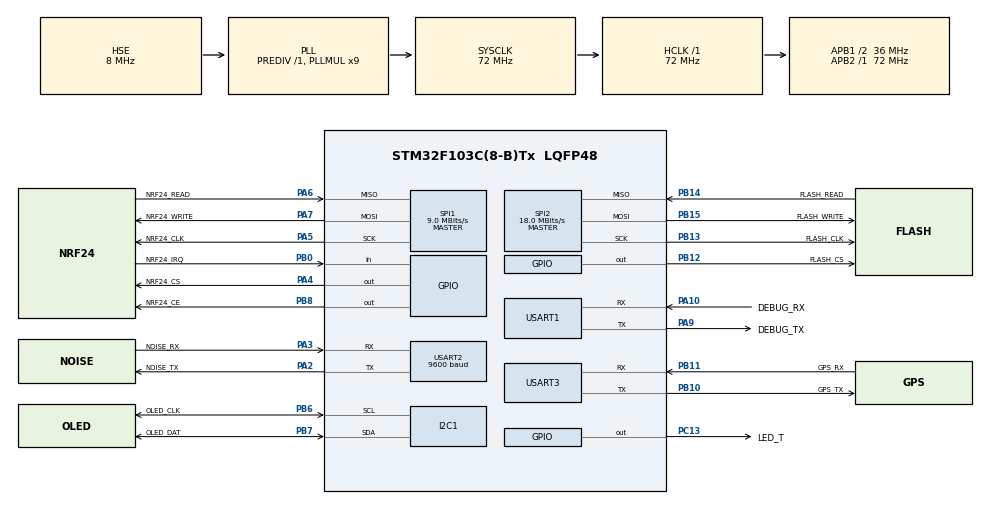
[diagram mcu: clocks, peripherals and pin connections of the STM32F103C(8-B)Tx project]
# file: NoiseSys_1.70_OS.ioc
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Dma.Request0=USART3_RX
Dma.USART3_RX.0.Direction=DMA_PERIPH_TO_MEMORY
Dma.USART3_RX.0.Instance=DMA1_Channel3
Dma.USART3_RX.0.MemDataAlignment=DMA_MDATAALIGN_BYTE
Dma.USART3_RX.0.MemInc=DMA_MINC_ENABLE
Dma.USART3_RX.0.Mode=DMA_NORMAL
Dma.USART3_RX.0.PeriphDataAlignment=DMA_PDATAALIGN_BYTE
Dma.USART3_RX.0.PeriphInc=DMA_PINC_DISABLE
Dma.USART3_RX.0.Priority=DMA_PRIORITY_LOW
FREERTOS.Tasks01=defaultTask,24,128,StartDefaultTask,Default,NULL,Static,defaultTaskBuffer,defaultTaskControlBlock
FREERTOS.configTOTAL_HEAP_SIZE=10240
I2C1.I2C_Mode=I2C_Standard
Mcu.Family=STM32F1
Mcu.Name=STM32F103C(8-B)Tx
Mcu.Package=LQFP48
NVIC.DMA1_Channel3_IRQn=true\:5\:0\:false\:false\:true\:true\:false\:true\:true
NVIC.PriorityGroup=NVIC_PRIORITYGROUP_4
NVIC.TIM4_IRQn=true\:15\:0\:false\:false\:true\:false\:false\:true\:true
NVIC.TimeBase=TIM4_IRQn
NVIC.TimeBaseIP=TIM4
NVIC.USART3_IRQn=true\:5\:0\:false\:false\:true\:true\:true\:true\:true
PA10.GPIO_Label=DEBUG_RX
PA10.Mode=Asynchronous
PA10.Signal=USART1_RX
PA13.Mode=Serial_Wire
PA13.Signal=SYS_JTMS-SWDIO
PA14.Mode=Serial_Wire
PA14.Signal=SYS_JTCK-SWCLK
PA2.GPIO_Label=NOISE_TX
PA2.Mode=Asynchronous
PA2.Signal=USART2_TX
PA3.GPIO_Label=NOISE_RX
PA3.Mode=Asynchronous
PA3.Signal=USART2_RX
PA4.GPIO_Label=NRF24_CS
PA4.Signal=GPIO_Output
PA5.GPIO_Label=NRF24_CLK
PA5.Mode=Full_Duplex_Master
PA5.Signal=SPI1_SCK
PA6.GPIO_Label=NRF24_READ
PA6.Mode=Full_Duplex_Master
PA6.Signal=SPI1_MISO
PA7.GPIO_Label=NRF24_WRITE
PA7.Mode=Full_Duplex_Master
PA7.Signal=SPI1_MOSI
PA9.GPIO_Label=DEBUG_TX
PA9.Mode=Asynchronous
PA9.Signal=USART1_TX
PB0.GPIO_Label=NRF24_IRQ
PB0.GPIO_PuPd=GPIO_PULLUP
PB0.Signal=GPIO_Input
PB10.GPIO_Label=GPS_TX
PB10.Mode=Asynchronous
PB10.Signal=USART3_TX
PB11.GPIO_Label=GPS_RX
PB11.Mode=Asynchronous
PB11.Signal=USART3_RX
PB12.GPIO_Label=FLASH_CS
PB12.Signal=GPIO_Output
PB13.GPIO_Label=FLASH_CLK
PB13.Mode=Full_Duplex_Master
PB13.Signal=SPI2_SCK
PB14.GPIO_Label=FLASH_READ
PB14.Mode=Full_Duplex_Master
PB14.Signal=SPI2_MISO
PB15.GPIO_Label=FLASH_WRITE
PB15.Mode=Full_Duplex_Master
PB15.Signal=SPI2_MOSI
PB6.GPIO_Label=OLED_CLK
PB6.Mode=I2C
PB6.Signal=I2C1_SCL
PB7.GPIO_Label=OLED_DAT
PB7.Mode=I2C
PB7.Signal=I2C1_SDA
PB8.GPIO_Label=NRF24_CE
PB8.Signal=GPIO_Output
PC13-TAMPER-RTC.GPIO_Label=LED_T
PC13-TAMPER-RTC.Signal=GPIO_Output
PD0-OSC_IN.Mode=HSE-External-Oscillator
PD0-OSC_IN.Signal=RCC_OSC_IN
PD1-OSC_OUT.Mode=HSE-External-Oscillator
PD1-OSC_OUT.Signal=RCC_OSC_OUT
ProjectManager.HeapSize=0x200
ProjectManager.StackSize=0x400
ProjectManager.TargetToolchain=MDK-ARM V5.32
RCC.AHBFreq_Value=72000000
RCC.APB1CLKDivider=RCC_HCLK_DIV2
RCC.APB1Freq_Value=36000000
RCC.APB1TimFreq_Value=72000000
RCC.APB2Freq_Value=72000000
RCC.APB2TimFreq_Value=72000000
RCC.HCLKFreq_Value=72000000
RCC.PLLMUL=RCC_PLL_MUL9
RCC.PLLSourceVirtual=RCC_PLLSOURCE_HSE
RCC.SYSCLKFreq_VALUE=72000000
RCC.SYSCLKSource=RCC_SYSCLKSOURCE_PLLCLK
RCC.USBFreq_Value=72000000
SPI1.BaudRatePrescaler=SPI_BAUDRATEPRESCALER_8
SPI1.CalculateBaudRate=9.0 MBits/s
SPI1.Direction=SPI_DIRECTION_2LINES
SPI1.Mode=SPI_MODE_MASTER
SPI1.VirtualType=VM_MASTER
SPI2.CalculateBaudRate=18.0 MBits/s
SPI2.Direction=SPI_DIRECTION_2LINES
SPI2.Mode=SPI_MODE_MASTER
SPI2.VirtualType=VM_MASTER
USART1.VirtualMode=VM_ASYNC
USART2.BaudRate=9600
USART2.VirtualMode=VM_ASYNC
USART3.VirtualMode=VM_ASYNC
VP_FREERTOS_VS_CMSIS_V2.Mode=CMSIS_V2
VP_SYS_VS_tim4.Mode=TIM4
board=custom

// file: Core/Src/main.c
/* USER CODE BEGIN Header */
/**
 ******************************************************************************
 * @file           : main.c
 * @brief          : Main program body
 ******************************************************************************
 * @attention
 *
 * Copyright (c) 2024 STMicroelectronics.
 * All rights reserved.
 *
 * This software is licensed under terms that can be found in the LICENSE file
 * in the root directory of this software component.
 * If no LICENSE file comes with this software, it is provided AS-IS.
 *
 ******************************************************************************
 */
/* USER CODE END Header */
#include "main.h"
#include "cmsis_os.h"
#include "dma.h"
#include "i2c.h"
#include "spi.h"
#include "usart.h"
#include "gpio.h"

void SystemClock_Config(void);
void MX_FREERTOS_Init(void);

int main(void)
{

    /* MCU Configuration--------------------------------------------------------*/

    /* Reset of all peripherals, Initializes the Flash interface and the Systick. */
    HAL_Init();

    /* Configure the system clock */
    SystemClock_Config();

    /* Initialize all configured peripherals */
    MX_GPIO_Init();
    MX_DMA_Init();
    MX_I2C1_Init();
    MX_SPI1_Init();
    MX_SPI2_Init();
    MX_USART1_UART_Init();
    MX_USART2_UART_Init();
    MX_USART3_UART_Init();
    /* USER CODE BEGIN 2 */
    HAL_UART_Receive_DMA(&huart3, Air780_rec_buf, 10); // 通过DMA获取一段指定长度数据
    __HAL_UART_ENABLE_IT(&huart3, UART_IT_IDLE);       // 使能IDLE中断

    /* USER CODE END 2 */

    /* Init scheduler */
    osKernelInitialize(); /* Call init function for freertos objects (in freertos.c) */
    MX_FREERTOS_Init();

    /* Start scheduler */
    osKernelStart();

    /* We should never get here as control is now taken by the scheduler */
    /* Infinite loop */
    while (1)
    {

    }
}

void SystemClock_Config(void)
{
    RCC_OscInitTypeDef RCC_OscInitStruct = {0};
    RCC_ClkInitTypeDef RCC_ClkInitStruct = {0};

    /** Initializes the RCC Oscillators according to the specified parameters
     * in the RCC_OscInitTypeDef structure.
     */
    RCC_OscInitStruct.OscillatorType = RCC_OSCILLATORTYPE_HSE;
    RCC_OscInitStruct.HSEState = RCC_HSE_ON;
    RCC_OscInitStruct.HSEPredivValue = RCC_HSE_PREDIV_DIV1;
    RCC_OscInitStruct.HSIState = RCC_HSI_ON;
    RCC_OscInitStruct.PLL.PLLState = RCC_PLL_ON;
    RCC_OscInitStruct.PLL.PLLSource = RCC_PLLSOURCE_HSE;
    RCC_OscInitStruct.PLL.PLLMUL = RCC_PLL_MUL9;
    if (HAL_RCC_OscConfig(&RCC_OscInitStruct) != HAL_OK)
    {
        Error_Handler();
    }

    /** Initializes the CPU, AHB and APB buses clocks
     */
    RCC_ClkInitStruct.ClockType = RCC_CLOCKTYPE_HCLK | RCC_CLOCKTYPE_SYSCLK | RCC_CLOCKTYPE_PCLK1 | RCC_CLOCKTYPE_PCLK2;
    RCC_ClkInitStruct.SYSCLKSource = RCC_SYSCLKSOURCE_PLLCLK;
    RCC_ClkInitStruct.AHBCLKDivider = RCC_SYSCLK_DIV1;
    RCC_ClkInitStruct.APB1CLKDivider = RCC_HCLK_DIV2;
    RCC_ClkInitStruct.APB2CLKDivider = RCC_HCLK_DIV1;

    if (HAL_RCC_ClockConfig(&RCC_ClkInitStruct, FLASH_LATENCY_2) != HAL_OK)
    {
        Error_Handler();
    }
}

void HAL_TIM_PeriodElapsedCallback(TIM_HandleTypeDef *htim)
{
    if (htim->Instance == TIM4)
    {
        HAL_IncTick();
    }
}

void Error_Handler(void)
{
    __disable_irq();
    while (1)
    {
    }
}

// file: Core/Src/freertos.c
/* USER CODE BEGIN Header */
/**
 ******************************************************************************
 * File Name          : freertos.c
 * Description        : Code for freertos applications
 ******************************************************************************
 * @attention
 *
 * Copyright (c) 2024 STMicroelectronics.
 * All rights reserved.
 *
 * This software is licensed under terms that can be found in the LICENSE file
 * in the root directory of this software component.
 * If no LICENSE file comes with this software, it is provided AS-IS.
 *
 ******************************************************************************
 */
/* USER CODE END Header */

#include "FreeRTOS.h"
#include "task.h"
#include "main.h"
#include "cmsis_os.h"

/* USER CODE BEGIN Includes */
#include "user_TasksInit.h"
/* USER CODE END Includes */

typedef StaticTask_t osStaticThreadDef_t;

/* Definitions for defaultTask */
// osThreadId_t defaultTaskHandle;
// uint32_t defaultTaskBuffer[128];
// osStaticThreadDef_t defaultTaskControlBlock;
// const osThreadAttr_t defaultTask_attributes = {
//     .name = "defaultTask",
//     .cb_mem = &defaultTaskControlBlock,
//     .cb_size = sizeof(defaultTaskControlBlock),
//     .stack_mem = &defaultTaskBuffer[0],
//     .stack_size = sizeof(defaultTaskBuffer),
//     .priority = (osPriority_t)osPriorityNormal,
// };

// void StartDefaultTask(void *argument);

void MX_FREERTOS_Init(void); /* (MISRA C 2004 rule 8.1) */

void MX_FREERTOS_Init(void)
{
    /* USER CODE BEGIN Init */
    User_Tasks_Init();
    /* USER CODE END Init */

    /* Create the thread(s) */
    /* creation of defaultTask */
    // defaultTaskHandle = osThreadNew(StartDefaultTask, NULL, &defaultTask_attributes);

}

void StartDefaultTask(void *argument)
{
    /* USER CODE BEGIN StartDefaultTask */
    /* Infinite loop */
    for (;;)
    {
        osDelay(0xffffffff);
    }
    /* USER CODE END StartDefaultTask */
}
